VERSION ""

NS_ :

BS_:

BU_: Airbag System

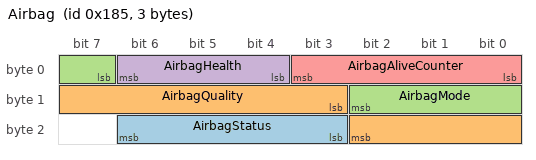
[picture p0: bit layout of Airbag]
BO_ 389 Airbag: 3 Airbag
 SG_ AirbagStatus : 19|4@1+ (1,0) [0.0|15.0] "code"  System
 SG_ AirbagQuality : 11|8@1+ (0.5,0.0) [0.0|100.0] "%"  System
 SG_ AirbagMode : 7|4@1+ (1,0) [0.0|15.0] "code"  System
 SG_ AirbagHealth : 4|3@1+ (1,0) [0.0|7.0] "code"  System
 SG_ AirbagAliveCounter : 0|4@1+ (1,0) [0.0|15.0] "count"  System

CM_ BO_ 389 "CanonicalMessage=e4bc9a5e-3a03-487f-a9ac-4ec87cc0f572; Network=Passive_Sicherheit_04-S01; Technology=can_fd";
CM_ SG_ 389 AirbagStatus "CanonicalSignal=88597ea7-773f-48c6-bd8b-222582f459ad";
CM_ SG_ 389 AirbagQuality "CanonicalSignal=614acb88-9848-44bd-9899-18ca0e076125";
CM_ SG_ 389 AirbagMode "CanonicalSignal=bda4c0d7-1114-4fa1-ae89-94722af47334";
CM_ SG_ 389 AirbagHealth "CanonicalSignal=56d380a4-ae7c-4212-a8be-f229d97250f1";
CM_ SG_ 389 AirbagAliveCounter "CanonicalSignal=f4d155e5-3a1d-4c69-83e6-fc784c6fabca";
BA_DEF_ BO_  "VFrameFormat" ENUM  "StandardCAN","ExtendedCAN","StandardCAN_FD","ExtendedCAN_FD";
BA_DEF_DEF_  "VFrameFormat" "0";
BA_ "VFrameFormat" BO_ 389 2;
